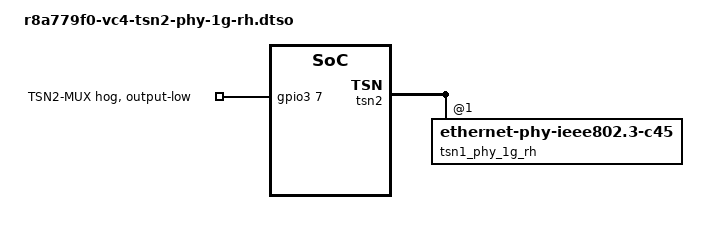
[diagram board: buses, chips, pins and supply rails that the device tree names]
/dts-v1/;
/plugin/;

#include <dt-bindings/gpio/gpio.h>

&gpio3 {
	tsn1-mux {
		gpio-hog;
		gpios = <7 GPIO_ACTIVE_HIGH>;
		output-low;
		line-name = "TSN2-MUX";
	};
};

&tsn2 {
	phy-mode = "sgmii";
	phy-handle = <&tsn2_phy_1g_rh>;

	#address-cells = <1>;
	#size-cells = <0>;

	tsn1_phy_1g_rh: ethernet-phy@1 {
		reg = <1>;
		compatible = "ethernet-phy-ieee802.3-c45";
		status = "okay";
	};
};
